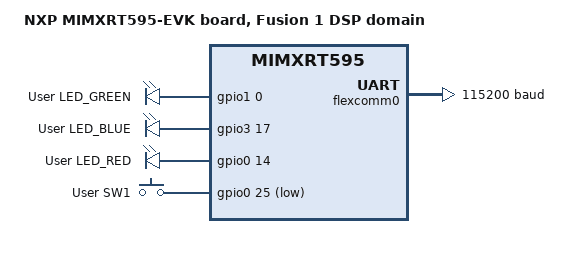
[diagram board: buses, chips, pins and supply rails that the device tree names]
/*
 * Copyright (c) 2023 Google LLC.
 * SPDX-License-Identifier: Apache-2.0
 */

/dts-v1/;


#include <nxp/nxp_rt595_f1.dtsi>
#include <zephyr/dt-bindings/gpio/gpio.h>

#include "mimxrt595_evk_mimxrt595s_cm33-pinctrl.dtsi"

/ {
	model = "NXP MIMXRT595-EVK board, Fusion 1 DSP domain";
	compatible = "nxp,mimxrt595";

	chosen {
		zephyr,console = &flexcomm0;
		zephyr,shell-uart = &flexcomm0;
	};
//
	aliases {
		led0 = &green_led;
		led1 = &blue_led;
		led2 = &red_led;
		sw0 = &user_button_1;
		mbox = &mbox;
	};

	leds: leds {
		compatible = "gpio-leds";

		green_led: led_1 {
			gpios = <&gpio1 0 0>;
			label = "User LED_GREEN";
		};

		blue_led: led_2 {
			gpios = <&gpio3 17 0>;
			label = "User LED_BLUE";
		};

		red_led: led_3 {
			gpios = <&gpio0 14 0>;
			label = "User LED_RED";
		};
	};

	gpio_keys {
		compatible = "gpio-keys";

		user_button_1: button_0 {
			label = "User SW1";
			gpios = <&gpio0 25 GPIO_ACTIVE_LOW>;
			zephyr,code = <INPUT_KEY_0>;
		};
	};
};

&gpio0 {
	status = "okay";
};

&gpio1 {
	status = "okay";
};

&dma0 {
	status = "okay";
};

&dma1 {
	status = "okay";
};

&flexcomm0 {
	compatible = "nxp,lpc-usart";
	pinctrl-0 = <&pinmux_flexcomm0_usart>;
	pinctrl-names = "default";
	current-speed = <115200>;
	status = "okay";
	dmas = <&dma0 0>, <&dma0 1>;
	dma-names = "rx", "tx";
};

&mbox {
	status = "okay";
};

